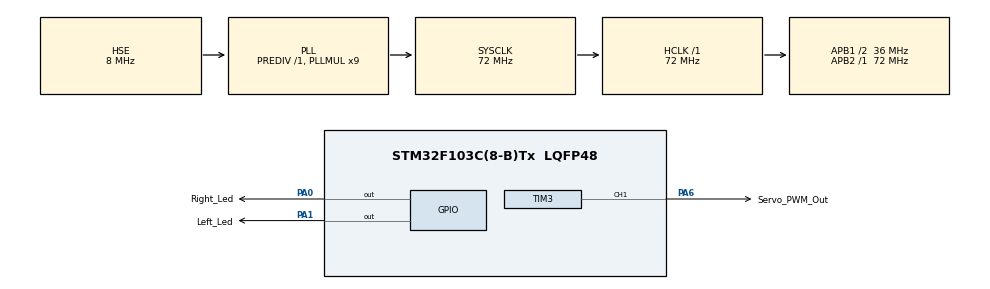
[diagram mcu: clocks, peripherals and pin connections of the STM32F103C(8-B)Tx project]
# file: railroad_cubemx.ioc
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Mcu.Family=STM32F1
Mcu.Name=STM32F103C(8-B)Tx
Mcu.Package=LQFP48
NVIC.PriorityGroup=NVIC_PRIORITYGROUP_4
PA0-WKUP.GPIO_Label=Right_Led
PA0-WKUP.Signal=GPIO_Output
PA1.GPIO_Label=Left_Led
PA1.Signal=GPIO_Output
PA13.Mode=Serial_Wire
PA13.Signal=SYS_JTMS-SWDIO
PA14.Mode=Serial_Wire
PA14.Signal=SYS_JTCK-SWCLK
PA6.GPIO_Label=Servo_PWM_Out
PA6.Signal=S_TIM3_CH1
PC14-OSC32_IN.Mode=LSE-External-Oscillator
PC14-OSC32_IN.Signal=RCC_OSC32_IN
PC15-OSC32_OUT.Mode=LSE-External-Oscillator
PC15-OSC32_OUT.Signal=RCC_OSC32_OUT
PD0-OSC_IN.Mode=HSE-External-Oscillator
PD0-OSC_IN.Signal=RCC_OSC_IN
PD1-OSC_OUT.Mode=HSE-External-Oscillator
PD1-OSC_OUT.Signal=RCC_OSC_OUT
ProjectManager.HeapSize=0x200
ProjectManager.StackSize=0x400
ProjectManager.TargetToolchain=Other Toolchains (GPDSC)
RCC.AHBFreq_Value=72000000
RCC.APB1CLKDivider=RCC_HCLK_DIV2
RCC.APB1Freq_Value=36000000
RCC.APB1TimFreq_Value=72000000
RCC.APB2Freq_Value=72000000
RCC.APB2TimFreq_Value=72000000
RCC.HCLKFreq_Value=72000000
RCC.PLLMUL=RCC_PLL_MUL9
RCC.PLLSourceVirtual=RCC_PLLSOURCE_HSE
RCC.SYSCLKFreq_VALUE=72000000
RCC.SYSCLKSource=RCC_SYSCLKSOURCE_PLLCLK
RCC.USBFreq_Value=72000000
SH.S_TIM3_CH1.0=TIM3_CH1,PWM Generation1 CH1
TIM3.Channel-PWM\ Generation1\ CH1=TIM_CHANNEL_1
TIM3.Period=1800-1
TIM3.Prescaler=800-1
TIM3.Pulse-PWM\ Generation1\ CH1=90
VP_TIM3_VS_ClockSourceINT.Mode=Internal
board=custom

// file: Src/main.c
/**
  ******************************************************************************
  * @file           : main.c
  * @brief          : Main program body
  ******************************************************************************
  ** This notice applies to any and all portions of this file
  * that are not between comment pairs USER CODE BEGIN and
  * USER CODE END. Other portions of this file, whether
  * inserted by the user or by software development tools
  * are owned by their respective copyright owners.
  *
  * COPYRIGHT(c) 2018 STMicroelectronics
  *
  * Redistribution and use in source and binary forms, with or without modification,
  * are permitted provided that the following conditions are met:
  *   1. Redistributions of source code must retain the above copyright notice,
  *      this list of conditions and the following disclaimer.
  *   2. Redistributions in binary form must reproduce the above copyright notice,
  *      this list of conditions and the following disclaimer in the documentation
  *      and/or other materials provided with the distribution.
  *   3. Neither the name of STMicroelectronics nor the names of its contributors
  *      may be used to endorse or promote products derived from this software
  *      without specific prior written permission.
  *
  * THIS SOFTWARE IS PROVIDED BY THE COPYRIGHT HOLDERS AND CONTRIBUTORS "AS IS"
  * AND ANY EXPRESS OR IMPLIED WARRANTIES, INCLUDING, BUT NOT LIMITED TO, THE
  * IMPLIED WARRANTIES OF MERCHANTABILITY AND FITNESS FOR A PARTICULAR PURPOSE ARE
  * DISCLAIMED. IN NO EVENT SHALL THE COPYRIGHT HOLDER OR CONTRIBUTORS BE LIABLE
  * FOR ANY DIRECT, INDIRECT, INCIDENTAL, SPECIAL, EXEMPLARY, OR CONSEQUENTIAL
  * DAMAGES (INCLUDING, BUT NOT LIMITED TO, PROCUREMENT OF SUBSTITUTE GOODS OR
  * SERVICES; LOSS OF USE, DATA, OR PROFITS; OR BUSINESS INTERRUPTION) HOWEVER
  * CAUSED AND ON ANY THEORY OF LIABILITY, WHETHER IN CONTRACT, STRICT LIABILITY,
  * OR TORT (INCLUDING NEGLIGENCE OR OTHERWISE) ARISING IN ANY WAY OUT OF THE USE
  * OF THIS SOFTWARE, EVEN IF ADVISED OF THE POSSIBILITY OF SUCH DAMAGE.
  *
  ******************************************************************************
  */
#include "main.h"
#include "stm32f1xx_hal.h"
#include "tim.h"
#include "gpio.h"

/* USER CODE BEGIN Includes */
#include "bell.h"
/* USER CODE END Includes */

/* USER CODE BEGIN PV */
/* Private variables ---------------------------------------------------------*/
#define UP        0
#define DOWN      1
#define GO_UP     -1
#define GO_DOWN    1
#define ANGLE_PWM_COMPARE_MIN                   90
#define BARRIER_START_ANGLE                      0
#define BARRIER_STOP_ANGLE                      90
#define BARRIER_ANGLE_STEP_INTERVAL_MS         40UL
uint8_t barrier_state = UP;

#define LIGHTS_TOGGLE_INTERVAL_MS 1000UL
/* USER CODE END PV */

void SystemClock_Config(void);

/* USER CODE BEGIN PFP */
/* Private function prototypes -----------------------------------------------*/

void Run_Lights(void) {
  static uint32_t last_tick = 0;

  if ((HAL_GetTick() - last_tick) >= LIGHTS_TOGGLE_INTERVAL_MS) {
    HAL_GPIO_TogglePin(GPIOA, Right_Led_Pin);
    HAL_GPIO_WritePin(GPIOA, Left_Led_Pin, !HAL_GPIO_ReadPin(GPIOA, Right_Led_Pin));
    last_tick = HAL_GetTick();
  }
}

void Run_Servo_Barrier(int8_t direction) {
  // 1 -> 1,5ms <=> 0 -> 90 degrees
  static uint32_t last_tick = 0;
  uint16_t current_angle = __HAL_TIM_GET_COMPARE(&htim3, TIM_CHANNEL_1) - ANGLE_PWM_COMPARE_MIN;

  if ((direction == GO_DOWN) && (current_angle >= (BARRIER_STOP_ANGLE / 2))) {
    barrier_state = DOWN;
    return;
  }

  if ((direction == GO_UP) && (current_angle <= BARRIER_START_ANGLE)) {
    barrier_state = UP;
    return;
  }

  if (HAL_GetTick() - last_tick >= BARRIER_ANGLE_STEP_INTERVAL_MS) {
    __HAL_TIM_SET_COMPARE(&htim3, TIM_CHANNEL_1, direction + __HAL_TIM_GET_COMPARE(&htim3, TIM_CHANNEL_1));
    last_tick = HAL_GetTick();
  }
}

/* USER CODE END PFP */

int main(void)
{

  /* MCU Configuration----------------------------------------------------------*/

  /* Reset of all peripherals, Initializes the Flash interface and the Systick. */
  HAL_Init();

  /* Configure the system clock */
  SystemClock_Config();

  /* Initialize all configured peripherals */
  MX_GPIO_Init();
  MX_TIM3_Init();
  /* USER CODE BEGIN 2 */
  HAL_TIM_PWM_Start(&htim3, TIM_CHANNEL_1);
  /* USER CODE END 2 */

  /* Infinite loop */
  while (1)
  {

  /* USER CODE BEGIN 3 */
    Run_Lights();
    if (barrier_state == UP) {
      Run_Servo_Barrier(GO_DOWN);
    }

    //HAL_Delay(1000);

    if (barrier_state == DOWN) {
      Run_Servo_Barrier(GO_UP);
    }
  }
  /* USER CODE END 3 */

}

void SystemClock_Config(void)
{

  RCC_OscInitTypeDef RCC_OscInitStruct;
  RCC_ClkInitTypeDef RCC_ClkInitStruct;

    /**Initializes the CPU, AHB and APB busses clocks
    */
  RCC_OscInitStruct.OscillatorType = RCC_OSCILLATORTYPE_HSE;
  RCC_OscInitStruct.HSEState = RCC_HSE_ON;
  RCC_OscInitStruct.HSEPredivValue = RCC_HSE_PREDIV_DIV1;
  RCC_OscInitStruct.HSIState = RCC_HSI_ON;
  RCC_OscInitStruct.PLL.PLLState = RCC_PLL_ON;
  RCC_OscInitStruct.PLL.PLLSource = RCC_PLLSOURCE_HSE;
  RCC_OscInitStruct.PLL.PLLMUL = RCC_PLL_MUL9;
  if (HAL_RCC_OscConfig(&RCC_OscInitStruct) != HAL_OK)
  {
    _Error_Handler(__FILE__, __LINE__);
  }

    /**Initializes the CPU, AHB and APB busses clocks
    */
  RCC_ClkInitStruct.ClockType = RCC_CLOCKTYPE_HCLK|RCC_CLOCKTYPE_SYSCLK
                              |RCC_CLOCKTYPE_PCLK1|RCC_CLOCKTYPE_PCLK2;
  RCC_ClkInitStruct.SYSCLKSource = RCC_SYSCLKSOURCE_PLLCLK;
  RCC_ClkInitStruct.AHBCLKDivider = RCC_SYSCLK_DIV1;
  RCC_ClkInitStruct.APB1CLKDivider = RCC_HCLK_DIV2;
  RCC_ClkInitStruct.APB2CLKDivider = RCC_HCLK_DIV1;

  if (HAL_RCC_ClockConfig(&RCC_ClkInitStruct, FLASH_LATENCY_2) != HAL_OK)
  {
    _Error_Handler(__FILE__, __LINE__);
  }

    /**Configure the Systick interrupt time
    */
  HAL_SYSTICK_Config(HAL_RCC_GetHCLKFreq()/1000);

    /**Configure the Systick
    */
  HAL_SYSTICK_CLKSourceConfig(SYSTICK_CLKSOURCE_HCLK);

  /* SysTick_IRQn interrupt configuration */
  HAL_NVIC_SetPriority(SysTick_IRQn, 0, 0);
}

void _Error_Handler(char *file, int line)
{
  while(1)
  {
  }
}

/************************ (C) COPYRIGHT STMicroelectronics *****END OF FILE****/
